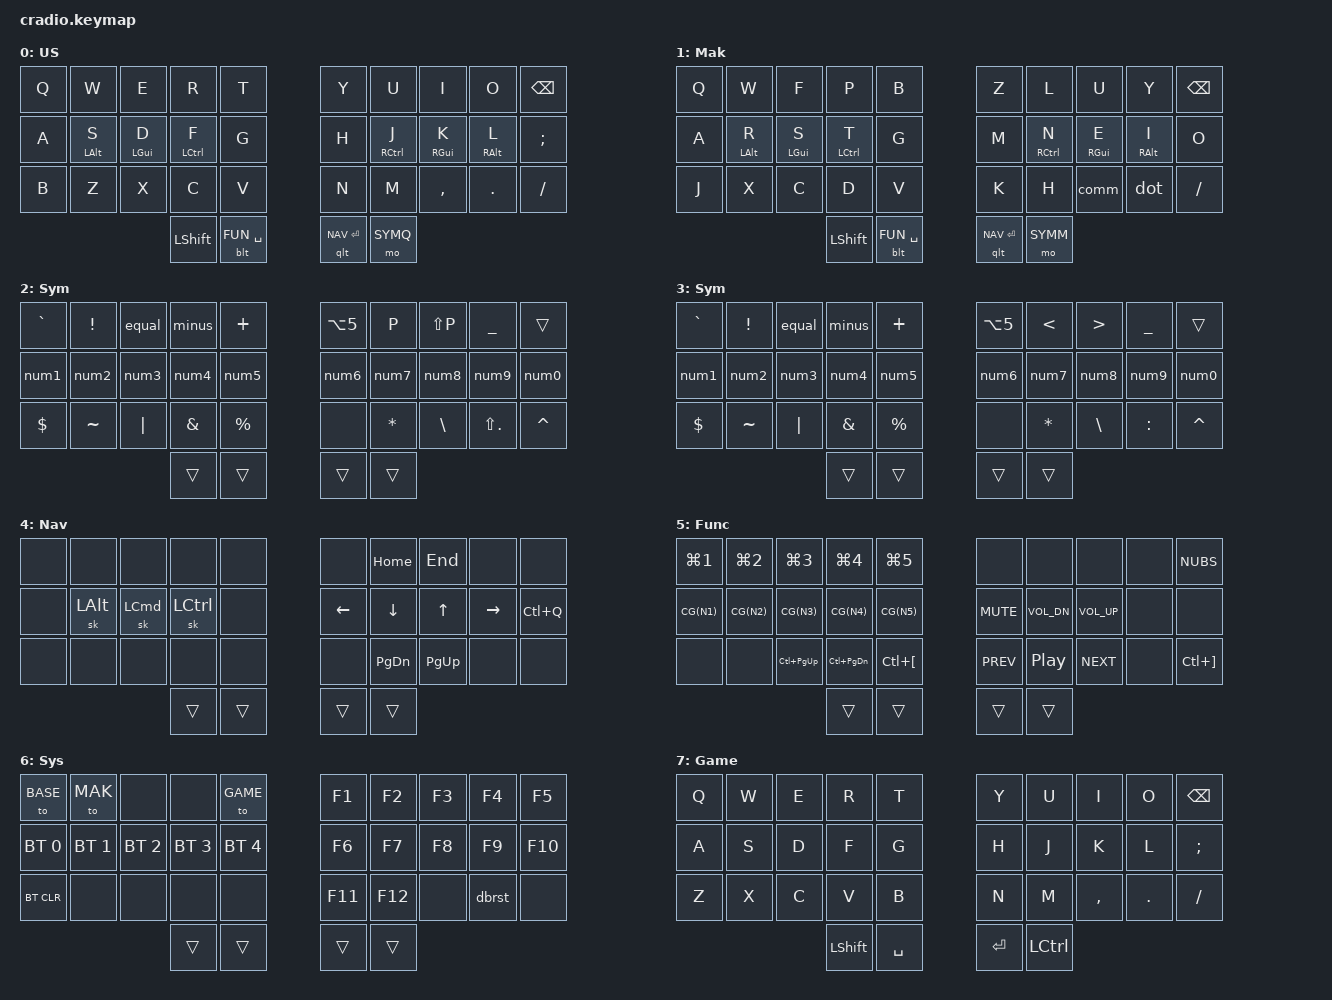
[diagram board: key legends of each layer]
#include <behaviors.dtsi>
#include <dt-bindings/zmk/keys.h>
#include <dt-bindings/zmk/rgb.h>
#include <dt-bindings/zmk/bt.h>
#include <dt-bindings/zmk/outputs.h>
#include <dt-bindings/zmk/pointing.h>

    
/ {
    #define SWEEP
    #include "smol.dtsi"

    keymap {
        compatible = "zmk,keymap";

        default_layer {
            display-name = "US";
            bindings = <
                &kp Q      &kp W       &kp E       &kp R          &kp T          &kp Y          &kp U          &kp I       &kp O       &kp BSPC
                &kp A      &hml LALT S &hml LGUI D &hml LCTRL F   &kp G          &kp H          &hmr RCTRL J   &hmr RGUI K &hmr RALT L &kp SEMI
                &kp B      &kp Z       &kp X       &kp C          &kp V          &kp N          &kp M          &kp COMMA   &kp DOT     &kp FSLH
                                                   &kp LSHFT      &blt FUN SPACE &qlt NAV RET   &mo SYMQ
            >;
        };
        mak_layer {
            display-name = "Mak";
            bindings = <
                &kp Q      &kp W       &kp F       &kp P          &kp B          &kp Z          &kp L          &kp U       &kp Y       &kp BSPC
                &kp A      &hml LALT R &hml LGUI S &hml LCTRL T   &kp G          &kp M          &hmr RCTRL N   &hmr RGUI E &hmr RALT I &kp O
                &kp J      &kp X       &kp C       &kp D          &kp V          &kp K          &kp H          &comm       &dot        &kp FSLH
                                                   &kp LSHFT      &blt FUN SPACE &qlt NAV RET   &mo SYMM    
            >;
        };
        sym_qwerty {
            display-name = "Sym";   
            bindings = <
                &kp GRAVE  &kp EXCL   &equal      &minus          &kp PLUS      &kp LA(N5)      &kp P          &kp LS(P)   &kp UNDER  &trans   
                &num1      &num2      &num3       &num4           &num5         &num6           &num7          &num8       &num9      &num0    
                &kp DLLR   &kp TILDE  &kp PIPE    &kp AMPS        &kp PRCNT     &none           &kp STAR       &kp BSLH    &kp LS(DOT)&kp CARET 
                                                  &trans          &trans        &trans          &trans
            >;
        };
        sym_mak {
            display-name = "Sym";   
            bindings = <
                &kp GRAVE  &kp EXCL   &equal      &minus          &kp PLUS      &kp LA(N5)      &kp LT         &kp GT      &kp UNDER  &trans   
                &num1      &num2      &num3       &num4           &num5         &num6           &num7          &num8       &num9      &num0    
                &kp DLLR   &kp TILDE  &kp PIPE    &kp AMPS        &kp PRCNT     &none           &kp STAR       &kp BSLH    &kp COLON  &kp CARET 
                                                  &trans          &trans        &trans          &trans
            >;
        };
        nav_layer {
            display-name = "Nav";
            bindings = <
                &none       &none       &none      &none          &none         &none           &kp HOME       &kp END      &none      &none   
                &none       &sk LALT    &sk LCMD   &sk LCTRL      &none         &kp LEFT        &kp DOWN       &kp UP       &kp RIGHT  &kp LC(Q)
                &none       &none       &none      &none          &none         &none           &kp PG_DN      &kp PG_UP    &none      &none 
                                                   &trans         &trans        &trans          &trans
            >;
        };
        function_layer {
            display-name = "Func";
            bindings = <
                &kp LG(N1)    &kp LG(N2)   &kp LG(N3)   &kp LG(N4)    &kp LG(N5)    &none      &none         &none        &none        &kp NUBS
                &kp CG(N1)    &kp CG(N2)   &kp CG(N3)   &kp CG(N4)    &kp CG(N5)    &kp C_MUTE &kp C_VOL_DN  &kp C_VOL_UP &none        &none      
                &none         &none        &kp LC(PG_UP)&kp LC(PG_DN) &kp LC(LBKT)  &kp C_PREV &kp C_PP      &kp C_NEXT   &none        &kp LC(RBKT)
                                                        &trans        &trans        &trans    &trans
            >;
        };
        system_layer {
            display-name = "Sys";
            bindings = <
                &to BASE     &to MAK        &none        &none          &to GAME     &kp F1    &kp F2        &kp F3       &kp F4       &kp F5
                &bt BT_SEL 0 &bt BT_SEL 1   &bt BT_SEL 2 &bt BT_SEL 3   &bt BT_SEL 4 &kp F6    &kp F7        &kp F8       &kp F9       &kp F10      
                &bt BT_CLR   &none          &none        &none          &none        &kp F11   &kp F12       &none        &dbrst       &none
                                                         &trans         &trans        &trans          &trans
            >;
        };
        game_layer {
            display-name = "Game";
            bindings = <
                &kp Q      &kp W       &kp E       &kp R          &kp T          &kp Y          &kp U          &kp I       &kp O       &kp BSPC
                &kp A      &kp S       &kp D       &kp F          &kp G          &kp H          &kp J          &kp K       &kp L       &kp SEMI
                &kp Z      &kp X       &kp C       &kp V          &kp B          &kp N          &kp M          &kp COMMA   &kp DOT     &kp FSLH
                                                   &kp LSHFT      &kp SPACE      &kp RET        &kp LCTRL
            >;
        };
    };
};
